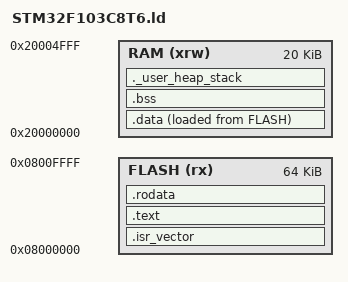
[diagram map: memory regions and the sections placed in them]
/* STM32F103C8T6 linker script */
/* 64KB Flash, 20KB RAM */

MEMORY
{
    FLASH (rx)  : ORIGIN = 0x08000000, LENGTH = 64K
    RAM   (xrw) : ORIGIN = 0x20000000, LENGTH = 20K
}

/* Entry Point */
ENTRY(Reset_Handler)

/* Highest address of the user mode stack */
_estack = ORIGIN(RAM) + LENGTH(RAM);

SECTIONS
{
    /* The startup code goes first into FLASH */
    .isr_vector :
    {
        . = ALIGN(4);
        KEEP(*(.isr_vector))
        . = ALIGN(4);
    } > FLASH

    /* The program code and other data goes into FLASH */
    .text :
    {
        . = ALIGN(4);
        *(.text)
        *(.text*)
        *(.glue_7)
        *(.glue_7t)
        *(.eh_frame)

        KEEP(*(.init))
        KEEP(*(.fini))

        . = ALIGN(4);
        _etext = .;
    } > FLASH

    /* Constant data goes into FLASH */
    .rodata :
    {
        . = ALIGN(4);
        *(.rodata)
        *(.rodata*)
        . = ALIGN(4);
    } > FLASH

    /* Used by the startup to initialize data */
    _sidata = LOADADDR(.data);

    /* Initialized data sections goes into RAM, load LMA copy after code */
    .data :
    {
        . = ALIGN(4);
        _sdata = .;
        *(.data)
        *(.data*)
        . = ALIGN(4);
        _edata = .;
    } > RAM AT > FLASH

    /* Uninitialized data section */
    . = ALIGN(4);
    .bss :
    {
        _sbss = .;
        __bss_start__ = _sbss;
        *(.bss)
        *(.bss*)
        *(COMMON)
        . = ALIGN(4);
        _ebss = .;
        __bss_end__ = _ebss;
    } > RAM

    /* User_heap_stack area, at the end of RAM */
    ._user_heap_stack :
    {
        . = ALIGN(8);
        PROVIDE(end = .);
        PROVIDE(_end = .);
        . = . + 0x400; /* 1KB heap */
        . = ALIGN(8);
        . = . + 0x400; /* 1KB stack */
        . = ALIGN(8);
    } > RAM

    .ARM.attributes 0 : { *(.ARM.attributes) }
}
